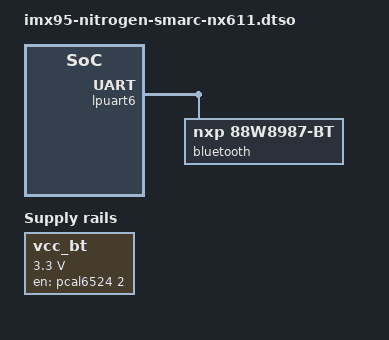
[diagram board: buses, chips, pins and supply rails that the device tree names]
// SPDX-License-Identifier: (GPL-2.0+ OR MIT)
/*
 * Copyright 2025 Ezurio LLC
 */

/dts-v1/;
/plugin/;

#include <dt-bindings/gpio/gpio.h>
#include <dt-bindings/interrupt-controller/irq.h>

&{/} {
	vcc_bt: regulator-bt {
		compatible = "regulator-fixed";
		regulator-name = "vcc_bt_en";
		regulator-min-microvolt = <3300000>;
		regulator-max-microvolt = <3300000>;
		gpios = <&pcal6524 2 GPIO_ACTIVE_HIGH>; /* BT_EN */
		enable-active-high;
	};
};

&lpuart6 {
	bluetooth {
		compatible = "nxp,88w8987-bt";
		fw-init-baudrate = <3000000>;
	};
};

&usdhc3 {
	#address-cells = <1>;
	#size-cells = <0>;
	/* Disable IF573 node */
	wifi@1 {
		reg = <1>;
		status = "disabled";
	};
};
